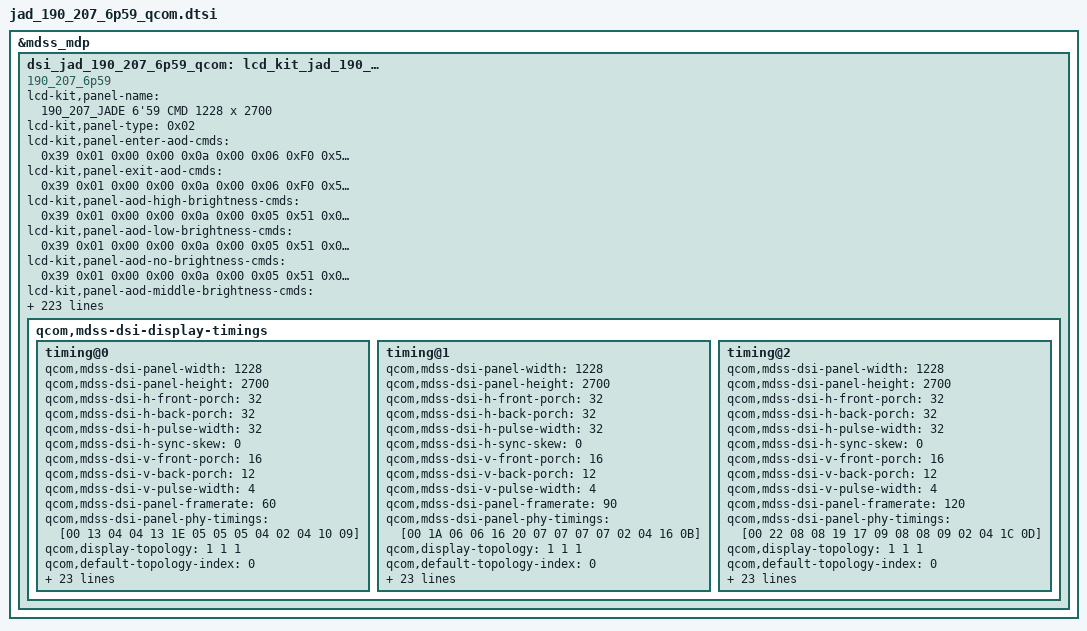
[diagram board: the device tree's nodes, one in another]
/* Copyright (c) 2013, The Linux Foundation. All rights reserved.
 *
 * This program is free software; you can redistribute it and/or modify
 * it under the terms of the GNU General Public License version 2 and
 * only version 2 as published by the Free Software Foundation.
 *
 * This program is distributed in the hope that it will be useful,
 * but WITHOUT ANY WARRANTY; without even the implied warranty of
 * MERCHANTABILITY or FITNESS FOR A PARTICULAR PURPOSE.  See the
 * GNU General Public License for more details.
 */

/*-------------------------------------------------------------------------
 * This file is autogenerated file using gcdb parser. Please do not edit it.
 * Update input XML file to add a new entry or update variable in this file
 * VERSION = 1.1
 *-----------------------------------------------------------------------*/
&mdss_mdp {
	dsi_jad_190_207_6p59_qcom: lcd_kit_jad_190_207_6p59_qcom {
		compatible = "190_207_6p59";
		lcd-kit,panel-name = "190_207_JADE 6'59 CMD 1228 x 2700";
		lcd-kit,panel-type = <0x02>;
		lcd-kit,panel-enter-aod-cmds = <0x39 0x01 0x00 0x00 0x0a 0x00 0x06 0xF0 0x55 0xAA 0x52 0x08 0x00
			0x15 0x01 0x00 0x00 0x0a 0x00 0x02 0x6F 0x0D
			0x15 0x01 0x00 0x00 0x0a 0x00 0x02 0xB5 0x50
			0x15 0x01 0x00 0x00 0x0a 0x00 0x02 0x2F 0x01
			0x05 0x01 0x00 0x00 0x0a 0x00 0x01 0x39
			0x05 0x01 0x00 0x00 0x0a 0x00 0x01 0x2C>;
		lcd-kit,panel-exit-aod-cmds = <0x39 0x01 0x00 0x00 0x0a 0x00 0x06 0xF0 0x55 0xAA 0x52 0x08 0x00
			0x15 0x01 0x00 0x00 0x0a 0x00 0x02 0x6F 0x0D
			0x15 0x01 0x00 0x00 0x0a 0x00 0x02 0xB5 0x4F
			0x05 0x01 0x00 0x00 0x0a 0x00 0x01 0x38
			0x05 0x01 0x00 0x00 0x0a 0x00 0x01 0x2C>;
		lcd-kit,panel-aod-high-brightness-cmds = <0x39 0x01 0x00 0x00 0x0a 0x00 0x05 0x51 0x00 0x00 0x0E 0xFE>;
		lcd-kit,panel-aod-low-brightness-cmds = <0x39 0x01 0x00 0x00 0x0a 0x00 0x05 0x51 0x00 0x00 0x07 0x5F>;
		lcd-kit,panel-aod-no-brightness-cmds = <0x39 0x01 0x00 0x00 0x0a 0x00 0x05 0x51 0x00 0x00 0x00 0x00>;
		lcd-kit,panel-aod-middle-brightness-cmds = <0x39 0x01 0x00 0x00 0x0a 0x00 0x05 0x51 0x00 0x00 0x0B 0xFE>;
		lcd-kit,panel-aod-off-cmds-state = "dsi_lp_mode";
		lcd-kit,pcd-check-reg-cmds = <0xcb>;
		lcd-kit,check-reg-on-cmds = <0x06 0x01 0x00 0x00 0x0a 0x00 0x01 0x0a>;
		lcd-kit,check-reg-on-value = <0x9c>;
		lcd-kit,check-aod-reg-on-cmds = <0x06 0x01 0x00 0x00 0x0a 0x00 0x01 0x0a>;
		lcd-kit,check-aod-reg-on-value = <0xdc>;
		lcd-kit,check-reg-off-cmds = <0x06 0x01 0x00 0x00 0x0a 0x00 0x01 0x0a>;
		lcd-kit,check-reg-off-value = <0x08>;
		lcd-kit,check-reg-on-cmds-state = "dsi_lp_mode";
		lcd-kit,check-aod-reg-on-cmds-state = "dsi_lp_mode";
		lcd-kit,check-reg-off-cmds-state = "dsi_lp_mode";
		lcd-kit,pcd-check-reg-value = <0xcb>;
		lcd-kit,pcd-errflag-check-support = <0>;
		lcd-kit,checksum-enable-cmds = <0x29 0x01 0x00 0x00 0x14 0x01 0x05 0xFF 0xAA 0x55 0xA5 0x80
			0x15 0x01 0x00 0x00 0x0a 0x00 0x02 0xF2 0x03>;
		lcd-kit,checksum-enable-cmds-state = "dsi_lp_mode";
		lcd-kit,checksum-disable-cmds = <0x29 0x01 0x00 0x00 0x14 0x01 0x05 0xFF 0xAA 0x55 0xA5 0x80
			0x15 0x01 0x00 0x00 0x0a 0x00 0x02 0xF2 0x00>;
		lcd-kit,checksum-disable-cmds-state = "dsi_lp_mode";
		lcd-kit,checksum-cmds = <0x15 0x01 0x00 0x00 0x0a 0x00 0x02 0x6F 0x01
			0x06 0x01 0x00 0x00 0x0a 0x00 0x08 0xF2 0x00 0x00 0x00 0x00 0x00 0x00 0x00>;
		lcd-kit,checksum-cmds-state = "dsi_lp_mode";
		lcd-kit,checksum-value = <0x92 0x54 0xc4 0x40 0x0e 0xf1 0x84 0x3b
			0x51 0x64 0xf8 0xae 0x2e 0x8a 0x47 0x0e
			0xcf 0x63 0xba 0xaa 0xfe 0x26 0xb6 0x54>;
		lcd-kit,oneside-mode-left = <0x39 0x01 0x00 0x00 0x00 0x00 0x06 0xF0 0x55 0xAA 0x52 0x08 0x06
		0x39 0x01 0x00 0x00 0x00 0x00 0x06 0xB0 0x32 0x32 0x32 0x32 0x32
		0x39 0x01 0x00 0x00 0x00 0x00 0x06 0xB1 0x32 0x32 0x32 0x32 0x32
		0x39 0x01 0x00 0x00 0x00 0x00 0x06 0xB2 0x32 0x32 0x32 0x32 0x32
		0x15 0x01 0x00 0x00 0x00 0x00 0x02 0xB3 0x32>;
		lcd-kit,oneside-mode-right = <0x39 0x01 0x00 0x00 0x00 0x00 0x06 0xF0 0x55 0xAA 0x52 0x08 0x06
		0x39 0x01 0x00 0x00 0x00 0x00 0x06 0xB6 0x32 0x32 0x32 0x32 0x32
		0x39 0x01 0x00 0x00 0x00 0x00 0x06 0xB7 0x32 0x32 0x32 0x32 0x32
		0x39 0x01 0x00 0x00 0x00 0x00 0x06 0xB8 0x32 0x32 0x32 0x32 0x32
		0x15 0x01 0x00 0x00 0x00 0x00 0x02 0xB9 0x32>;
		lcd-kit,oneside-mode-exit = <0x39 0x01 0x00 0x00 0x00 0x00 0x06 0xF0 0x55 0xAA 0x52 0x08 0x06
		0x39 0x01 0x00 0x00 0x00 0x00 0x06 0xB0 0x28 0x04 0x04 0x13 0x13
		0x39 0x01 0x00 0x00 0x00 0x00 0x06 0xB1 0x12 0x12 0x32 0x00 0x00
		0x39 0x01 0x00 0x00 0x00 0x00 0x06 0xB2 0x0F 0x0F 0x0E 0x0E 0x32
		0x15 0x01 0x00 0x00 0x00 0x00 0x02 0xB3 0x32
		0x39 0x01 0x00 0x00 0x00 0x00 0x06 0xB6 0x28 0x04 0x04 0x13 0x13
		0x39 0x01 0x00 0x00 0x00 0x00 0x06 0xB7 0x12 0x12 0x32 0x00 0x00
		0x39 0x01 0x00 0x00 0x00 0x00 0x06 0xB8 0x0F 0x0F 0x0E 0x0E 0x32
		0x15 0x01 0x00 0x00 0x00 0x00 0x02 0xB9 0x32>;
		lcd-kit,color-aod-detect-enter = <0x39 0x01 0x00 0x00 0x00 0x00 0x06 0xF0 0x55 0xAA 0x52 0x08 0x00
		0x15 0x01 0x00 0x00 0x00 0x00 0x02 0x6F 0x0D
		0x15 0x01 0x00 0x00 0x00 0x00 0x02 0xB5 0x50
		0x15 0x01 0x00 0x00 0x00 0x00 0x02 0x2F 0x01
		0x05 0x01 0x00 0x00 0x00 0x00 0x01 0x39
		0x05 0x01 0x00 0x00 0x00 0x00 0x01 0x2C
		0x39 0x01 0x00 0x00 0x00 0x00 0x05 0x51 0x00 0x00 0x0E 0xFE>;
		lcd-kit,color-aod-detect-enter-state = "dsi_lp_mode";
		lcd-kit,color-aod-detect-exit = <0x39 0x01 0x00 0x00 0x00 0x00 0x06 0xF0 0x55 0xAA 0x52 0x08 0x00
		0x15 0x01 0x00 0x00 0x00 0x00 0x02 0x6F 0x0D
		0x15 0x01 0x00 0x00 0x00 0x00 0x02 0xB5 0x4F
		0x05 0x01 0x00 0x00 0x00 0x00 0x01 0x38
		0x05 0x01 0x00 0x00 0x00 0x00 0x01 0x2C>;
		lcd-kit,color-aod-detect-exit-state = "dsi_lp_mode";
		lcd-kit,hor-line-cmds = <0x39 0x01 0x00 0x00 0x0a 0x00 0x06 0xF0 0x55 0xAA 0x52 0x08 0x00
			0x15 0x01 0x00 0x00 0x0a 0x00 0x02 0xB5 0x90
			0x15 0x01 0x00 0x00 0x0a 0x00 0x02 0x6F 0x06
			0x15 0x01 0x00 0x00 0x0a 0x00 0x02 0xB5 0x4E
			0x39 0x01 0x00 0x00 0x0a 0x00 0x06 0xF0 0x55 0xAA 0x52 0x08 0x01
			0x15 0x01 0x00 0x00 0x0a 0x00 0x02 0xB0 0x03
			0x15 0x01 0x00 0x00 0x0a 0x00 0x02 0xB3 0x15
			0x39 0x01 0x00 0x00 0x0a 0x00 0x06 0xF0 0x55 0xAA 0x52 0x08 0x01
			0x15 0x01 0x00 0x00 0x0a 0x00 0x02 0xB7 0x32
			0x39 0x01 0x00 0x00 0x0a 0x00 0x06 0xF0 0x55 0xAA 0x52 0x08 0x01
			0x15 0x01 0x00 0x00 0x0a 0x00 0x02 0xB1 0x05
			0x15 0x01 0x00 0x00 0x0a 0x00 0x02 0xB4 0x15
			0x39 0x01 0x00 0x00 0x0a 0x00 0x06 0xF0 0x55 0xAA 0x52 0x08 0x01
			0x15 0x01 0x00 0x00 0x0a 0x00 0x02 0xB8 0x5F
			0x29 0x01 0x00 0x00 0x0a 0x00 0x06 0xF0 0x55 0xAA 0x52 0x08 0x01
			0x29 0x01 0x00 0x00 0x0a 0x00 0x03 0xB5 0x00 0xF8
			0x29 0x01 0x00 0x00 0x0a 0x00 0x03 0xB6 0x01 0x68
			0x29 0x01 0x00 0x00 0x0a 0x00 0x06 0xF0 0x55 0xAA 0x52 0x08 0x01
			0x29 0x01 0x00 0x00 0x0a 0x00 0x02 0xCF 0x00
			0x29 0x01 0x00 0x00 0x0a 0x00 0x06 0xF0 0x55 0xAA 0x52 0x08 0x07
			0x29 0x01 0x00 0x00 0x0a 0x00 0x02 0xB0 0x00
			0x39 0x01 0x00 0x00 0x0a 0x00 0x06 0xF0 0x55 0xAA 0x52 0x08 0x06
			0x39 0x01 0x00 0x00 0x0a 0x00 0x06 0xB0 0x28 0x31 0x31 0x13 0x13
			0x39 0x01 0x00 0x00 0x0a 0x00 0x06 0xB1 0x12 0x12 0x32 0x31 0x31
			0x39 0x01 0x00 0x00 0x0a 0x00 0x06 0xB6 0x28 0x31 0x31 0x13 0x13
			0x39 0x01 0x00 0x00 0x0a 0x00 0x06 0xB7 0x12 0x12 0x32 0x31 0x31
			0x39 0x01 0x00 0x00 0x0a 0x00 0x06 0xF0 0x55 0xAA 0x52 0x08 0x03
			0x15 0x01 0x00 0x00 0x0a 0x00 0x02 0x6F 0x0F
			0x15 0x01 0x00 0x00 0x0a 0x00 0x02 0xB6 0x1F
			0x15 0x01 0x00 0x00 0x0a 0x00 0x02 0x6F 0x18
			0x15 0x01 0x00 0x00 0x0a 0x00 0x02 0xB6 0x0F
			0x15 0x01 0x00 0x00 0x0a 0x00 0x02 0x6F 0x21
			0x15 0x01 0x00 0x00 0x0a 0x00 0x02 0xB6 0x0F
			0x15 0x01 0x00 0x00 0x0a 0x00 0x02 0x6F 0x2A
			0x15 0x01 0x00 0x00 0x0a 0x00 0x02 0xB6 0x0F
			0x05 0x01 0x00 0x00 0x0a 0x00 0x01 0x35
			0x15 0x01 0x00 0x00 0x0a 0x00 0x02 0x53 0x20
			0x39 0x01 0x00 0x00 0x0a 0x00 0x05 0x51 0x00 0x00 0x00 0x00
			0x39 0x01 0x00 0x00 0x0a 0x00 0x05 0x2A 0x00 0x00 0x04 0xCB
			0x39 0x01 0x00 0x00 0x0a 0x00 0x05 0x2B 0x00 0x00 0x0A 0x8B
			0x15 0x01 0x00 0x00 0x0a 0x00 0x02 0x90 0x01
			0x15 0x01 0x00 0x00 0x0a 0x00 0x02 0x03 0x01
			0x39 0x01 0x00 0x00 0x64 0x00 0x13 0x91 0x89 0x28 0x00 0x3C 0xF2 0x00 0x04 0x01 0x06 0xF5 0x00 0x11 0x02 0x09 0x00 0xBF 0x10 0xF0
			0x05 0x01 0x00 0x00 0x0a 0x00 0x01 0x2C
			0x15 0x01 0x00 0x00 0x0a 0x00 0x02 0x82 0xAC
			0x05 0x01 0x00 0x00 0x46 0x01 0x01 0x11
			0x15 0x01 0x00 0x00 0x0a 0x00 0x02 0x2F 0x01
			0x05 0x01 0x00 0x00 0x0a 0x00 0x01 0x29>;
		lcd-kit,hor-line-cmds-state = "dsi_lp_mode";
		lcd-kit,start-pcd-check-cmds = <0x39 0x01 0x00 0x00 0x00 0x00 0x06 0xF0 0x55 0xAA 0x52 0x08 0x01
		0x39 0x01 0x00 0x00 0x00 0x00 0x03 0xD0 0x00 0x31>;
		lcd-kit,pcd-read-cmds = <0x39 0x01 0x00 0x00 0x00 0x00 0x06 0xF0 0x55 0xAA 0x52 0x08 0x01
		0x15 0x01 0x00 0x00 0x00 0x00 0x02 0x6F 0x02
		0x06 0x01 0x00 0x00 0x00 0x00 0x01 0xD0>;
		lcd-kit,pcd-read-cmds-state  = "dsi_lp_mode";
		lcd-kit,vtc-line-cmds = <0x39 0x01 0x00 0x00 0x0a 0x00 0x06 0xF0 0x55 0xAA 0x52 0x08 0x00
			0x15 0x01 0x00 0x00 0x0a 0x00 0x02 0xB5 0x90
			0x15 0x01 0x00 0x00 0x0a 0x00 0x02 0x6F 0x06
			0x15 0x01 0x00 0x00 0x0a 0x00 0x02 0xB5 0x4E
			0x39 0x01 0x00 0x00 0x0a 0x00 0x06 0xF0 0x55 0xAA 0x52 0x08 0x01
			0x15 0x01 0x00 0x00 0x0a 0x00 0x02 0xB0 0x03
			0x15 0x01 0x00 0x00 0x0a 0x00 0x02 0xB3 0x15
			0x39 0x01 0x00 0x00 0x0a 0x00 0x06 0xF0 0x55 0xAA 0x52 0x08 0x01
			0x15 0x01 0x00 0x00 0x0a 0x00 0x02 0xB7 0x32
			0x39 0x01 0x00 0x00 0x0a 0x00 0x06 0xF0 0x55 0xAA 0x52 0x08 0x01
			0x15 0x01 0x00 0x00 0x0a 0x00 0x02 0xB1 0x05
			0x15 0x01 0x00 0x00 0x0a 0x00 0x02 0xB4 0x15
			0x39 0x01 0x00 0x00 0x0a 0x00 0x06 0xF0 0x55 0xAA 0x52 0x08 0x01
			0x15 0x01 0x00 0x00 0x0a 0x00 0x02 0xB8 0x5F
			0x29 0x01 0x00 0x00 0x0a 0x00 0x06 0xF0 0x55 0xAA 0x52 0x08 0x01
			0x29 0x01 0x00 0x00 0x0a 0x00 0x03 0xB5 0x00 0xF8
			0x29 0x01 0x00 0x00 0x0a 0x00 0x03 0xB6 0x01 0x68
			0x29 0x01 0x00 0x00 0x0a 0x00 0x06 0xF0 0x55 0xAA 0x52 0x08 0x01
			0x29 0x01 0x00 0x00 0x0a 0x00 0x02 0xCF 0x00
			0x29 0x01 0x00 0x00 0x0a 0x00 0x06 0xF0 0x55 0xAA 0x52 0x08 0x07
			0x29 0x01 0x00 0x00 0x0a 0x00 0x02 0xB0 0x00
			0x39 0x01 0x00 0x00 0x0a 0x00 0x06 0xF0 0x55 0xAA 0x52 0x08 0x06
			0x39 0x01 0x00 0x00 0x0a 0x00 0x06 0xB0 0x28 0x31 0x31 0x13 0x13
			0x39 0x01 0x00 0x00 0x0a 0x00 0x06 0xB1 0x12 0x12 0x32 0x31 0x31
			0x39 0x01 0x00 0x00 0x0a 0x00 0x06 0xB6 0x28 0x31 0x31 0x13 0x13
			0x39 0x01 0x00 0x00 0x0a 0x00 0x06 0xB7 0x12 0x12 0x32 0x31 0x31
			0x39 0x01 0x00 0x00 0x0a 0x00 0x06 0xF0 0x55 0xAA 0x52 0x08 0x03
			0x15 0x01 0x00 0x00 0x0a 0x00 0x02 0x6F 0x0F
			0x15 0x01 0x00 0x00 0x0a 0x00 0x02 0xB6 0x1F
			0x15 0x01 0x00 0x00 0x0a 0x00 0x02 0x6F 0x18
			0x15 0x01 0x00 0x00 0x0a 0x00 0x02 0xB6 0x0F
			0x15 0x01 0x00 0x00 0x0a 0x00 0x02 0x6F 0x21
			0x15 0x01 0x00 0x00 0x0a 0x00 0x02 0xB6 0x0F
			0x15 0x01 0x00 0x00 0x0a 0x00 0x02 0x6F 0x2A
			0x15 0x01 0x00 0x00 0x0a 0x00 0x02 0xB6 0x0F
			0x05 0x01 0x00 0x00 0x0a 0x00 0x01 0x35
			0x15 0x01 0x00 0x00 0x0a 0x00 0x02 0x53 0x20
			0x39 0x01 0x00 0x00 0x0a 0x00 0x05 0x51 0x00 0x00 0x00 0x00
			0x39 0x01 0x00 0x00 0x0a 0x00 0x05 0x2A 0x00 0x00 0x04 0xCB
			0x39 0x01 0x00 0x00 0x0a 0x00 0x05 0x2B 0x00 0x00 0x0A 0x8B
			0x15 0x01 0x00 0x00 0x0a 0x00 0x02 0x90 0x01
			0x15 0x01 0x00 0x00 0x0a 0x00 0x02 0x03 0x01
			0x39 0x01 0x00 0x00 0x64 0x00 0x13 0x91 0x89 0x28 0x00 0x3C 0xF2 0x00 0x04 0x01 0x06 0xF5 0x00 0x11 0x02 0x09 0x00 0xBF 0x10 0xF0
			0x05 0x01 0x00 0x00 0x0a 0x00 0x01 0x2C
			0x15 0x01 0x00 0x00 0x0a 0x00 0x02 0x82 0xAC
			0x05 0x01 0x00 0x00 0x46 0x01 0x01 0x11
			0x15 0x01 0x00 0x00 0x0a 0x00 0x02 0x2F 0x01
			0x05 0x01 0x00 0x00 0x0a 0x00 0x01 0x29>;
		lcd-kit,vtc-line-cmds-state  = "dsi_lp_mode";
		lcd-kit,ddic-lv-det-enter1-cmds = <0x39 0x01 0x00 0x00 0x0a 0x00 0x06 0xF0 0x55 0xAA 0x52 0x08 0x01
			0x15 0x01 0x00 0x00 0x0a 0x00 0x02 0xC7 0xA0
			0x15 0x01 0x00 0x00 0x0a 0x00 0x02 0x6F 0x03
			0x15 0x01 0x00 0x00 0x0a 0x00 0x02 0xC7 0x18>;
		lcd-kit,ddic-lv-det-enter1-cmds-state  = "dsi_lp_mode";
		lcd-kit,ddic-lv-det-enter2-cmds = <0x39 0x01 0x00 0x00 0x0a 0x00 0x06 0xF0 0x55 0xAA 0x52 0x08 0x01
			0x15 0x01 0x00 0x00 0x0a 0x00 0x02 0xC7 0xA0
			0x15 0x01 0x00 0x00 0x0a 0x00 0x02 0x6F 0x03
			0x15 0x01 0x00 0x00 0x0a 0x00 0x02 0xC7 0x18>;
		lcd-kit,ddic-lv-det-enter2-cmds-state  = "dsi_lp_mode";
		lcd-kit,ddic-lv-det-enter3-cmds = <0x39 0x01 0x00 0x00 0x0a 0x00 0x06 0xF0 0x55 0xAA 0x52 0x08 0x01
			0x15 0x01 0x00 0x00 0x0a 0x00 0x02 0xC7 0xA0
			0x15 0x01 0x00 0x00 0x0a 0x00 0x02 0x6F 0x03
			0x15 0x01 0x00 0x00 0x0a 0x00 0x02 0xC7 0x18>;
		lcd-kit,ddic-lv-det-enter3-cmds-state  = "dsi_lp_mode";
		lcd-kit,ddic-lv-det-enter4-cmds = <0x39 0x01 0x00 0x00 0x0a 0x00 0x06 0xF0 0x55 0xAA 0x52 0x08 0x01
			0x15 0x01 0x00 0x00 0x0a 0x00 0x02 0xC7 0xA0
			0x15 0x01 0x00 0x00 0x0a 0x00 0x02 0x6F 0x03
			0x15 0x01 0x00 0x00 0x0a 0x00 0x02 0xC7 0x18>;
		lcd-kit,ddic-lv-det-enter4-cmds-state  = "dsi_lp_mode";
		lcd-kit,ddic-lv-det-rd1-cmds = <0x06 0x01 0x00 0x00 0x0a 0x00 0x01 0x0a>;
		lcd-kit,ddic-lv-det-rd1-cmds-state  = "dsi_lp_mode";
		lcd-kit,ddic-lv-det-rd2-cmds = <0x06 0x01 0x00 0x00 0x0a 0x00 0x01 0x0a>;
		lcd-kit,ddic-lv-det-rd2-cmds-state  = "dsi_lp_mode";
		lcd-kit,ddic-lv-det-rd3-cmds = <0x06 0x01 0x00 0x00 0x0a 0x00 0x01 0x0a>;
		lcd-kit,ddic-lv-det-rd3-cmds-state  = "dsi_lp_mode";
		lcd-kit,ddic-lv-det-rd4-cmds = <0x06 0x01 0x00 0x00 0x0a 0x00 0x01 0x0a>;
		lcd-kit,ddic-lv-det-rd4-cmds-state  = "dsi_lp_mode";
		lcd-kit,ddic-lv-det-value1 = <0x9c>;
		lcd-kit,ddic-lv-det-value2 = <0x9c>;
		lcd-kit,ddic-lv-det-value3 = <0x9c>;
		lcd-kit,ddic-lv-det-value4 = <0x9c>;
		lcd-kit,ap-aod-support = <1>;
		lcd-kit,left-time-to-te-us = <25667>;
		lcd-kit,right-time-to-te-us = <26167>;
		lcd-kit,te-interval-time-us = <16667>;
		lcd-kit,oneside-mode-support = <1>;
		lcd-kit,color-aod-detect-support = <1>;
		lcd-kit,elvdd-detect-support = <0>;
		lcd-kit,elvdd-detect-type = <2>;
		lcd-kit,elvdd-detect-value = <1>;
		lcd-kit,elvdd-delay = <50>;
		lcd-kit,elvdd-detect-gpio = <104>;
		lcd-kit,check-reg-on-support = <0>;
		lcd-kit,check-reg-on-support-dsm-report = <0>;
		lcd-kit,check-aod-reg-on-support = <0>;
		lcd-kit,check-aod-reg-on-support-dsm-report = <0>;
		lcd-kit,check-reg-off-support = <0>;
		lcd-kit,check-reg-off-support-dsm-report = <0>;
		lcd-kit,checksum-support = <1>;
		lcd-kit,pcd-cmds-support = <1>;
		lcd-kit,pcd-check-reg-value-compare-mode = <1>;
		lcd-kit,vtc-line-support = <1>;
		lcd-kit,ddic-lv-det-support = <1>;
		lcd-kit,hor-line-support = <1>;
		lcd-kit,hor-line-duration = <600>;
		qcom,mdss-dsi-panel-type = "dsi_cmd_mode";
		qcom,mdss-pan-physical-width-dimension = <69>;
		qcom,mdss-pan-physical-height-dimension = <152>;
		qcom,dsi-ctrl-num = <0>;
		qcom,dsi-phy-num = <0>;
		qcom,panel-supply-entries = <&dsi_panel_pwr_supply>;
		qcom,mdss-dsi-virtual-channel-id = <0>;
		qcom,mdss-dsi-h-sync-pulse = <0>;
		qcom,mdss-dsi-bllp-eof-power-mode;
		qcom,mdss-dsi-bllp-power-mode;
		qcom,mdss-dsi-dma-schedule-line = <1>;
		qcom,mdss-dsi-bpp = <24>;
		qcom,mdss-dsi-color-order = "rgb_swap_rgb";
		qcom,mdss-dsi-underflow-color = <0xff>;
		qcom,mdss-dsi-border-color = <0>;
		qcom,mdss-dsi-traffic-mode = "burst_mode";
		qcom,mdss-dsi-lane-map = "lane_map_0123";
		qcom,mdss-dsi-lane-0-state;
		qcom,mdss-dsi-lane-1-state;
		qcom,mdss-dsi-lane-2-state;
		qcom,mdss-dsi-lane-3-state;
		qcom,mdss-dsi-mdp-trigger = "none";
		qcom,mdss-dsi-dma-trigger = "trigger_sw";
		qcom,mdss-dsi-te-pin-select = <1>;
		qcom,mdss-dsi-wr-mem-start = <0x2c>;
		qcom,mdss-dsi-wr-mem-continue = <0x3c>;
		qcom,mdss-dsi-te-dcs-command = <1>;
		qcom,mdss-dsi-te-check-enable;
		qcom,mdss-dsi-te-using-te-pin;
		qcom,mdss-dsi-t-clk-post = <0>;
		qcom,mdss-dsi-t-clk-pre = <0>;
		qcom,dsi-select-clocks = "mux_byte_clk0", "mux_pixel_clk0";
		qcom,mdss-dsi-stream = <0>;
		qcom,mdss-dsi-lp11-init;
		qcom,sublinks-count = <2>;
		qcom,lanes-per-sublink = <2>;
		qcom,mdss-dsi-panel-hdr-color-primaries = <14500 15500 32000 17000 15500 30000 8000 3000>;
		qcom,mdss-dsi-panel-peak-brightness = <4200000>;
		qcom,mdss-dsi-panel-blackness-level = <3230>;
		qcom,dynamic-mode-switch-enabled;
		qcom,dynamic-mode-switch-type = "dynamic-resolution-switch-immediate";
		qcom,mdss-dsi-bl-pmic-control-type = "bl_ctrl_dcs";
		qcom,mdss-dsi-bl-min-level = <1>;
		qcom,mdss-dsi-bl-max-level = <4095>;
		qcom,esd-check-enabled;
		qcom,mdss-dsi-panel-status-command = [06 01 00 00 00 00 01 0A];
		qcom,mdss-dsi-panel-status-command-state = "dsi_lp_mode";
		qcom,mdss-dsi-panel-status-check-mode = "reg_read";
		qcom,mdss-dsi-panel-status-read-length = <1>;
		qcom,mdss-dsi-panel-status-value = <0x9C>;
		lcd-kit,power-on-stage = <2 1 1
				9 1 1
				3 1 1
				1 1 10
				5 1 10
				7 1 0
				6 1 0
				8 1 0>;
		lcd-kit,lp-on-stage = <0 0 0>;
		lcd-kit,lp-off-stage = <0 0 0>;
		lcd-kit,power-off-stage = <7 0 0
				6 0 0
				8 0 0
				5 0 1
				1 0 1
				9 0 1
				3 0 1
				2 0 1>;
		lcd-kit,only-power-off-stage = <0 0 0>;
		lcd-kit,pt-support = <1>;
		lcd-kit,panel-on-always-reset = <0>;
		lcd-kit,lcd-vci = <1 13 3000000 3000000 3000000 10000 80>;
		lcd-kit,lcd-iovcc = <1 12 1800000 1800000 1800000 60700 80>;
		lcd-kit,lcd-vdd = <2 197 1200000>;
		lcd-kit,lcd-vsp = <1 1 1200000 1200000 1200000 60700 80>;
		lcd-kit,lcd-reset = <2 24 0>;
		lcd-kit,lcd-vci-name = "vdd";
		lcd-kit,lcd-iovcc-name = "vddio";
		lcd-kit,lcd-vsp-name = "ddic";
		lcd-kit,project-id-support = <0>;
		lcd-kit,default-project-id = "G240A7130";
		lcd-kit,sn-code-support = <1>;
		lcd-kit,oem-info-support = <1>;
		lcd-kit,oem-barcode-2d-support = <1>;
		lcd-kit,oem-barcode-2d-num-offset = <0>;
		lcd-kit,barcode-2d-cmds = <0x39 0x01 0x00 0x00 0x0a 0x00 0x06 0xF0 0x55 0xAA 0x52 0x08 0x01
                  0x14 0x01 0x00 0x00 0x0a 0x00 0x08 0xD6 0x00 0x00 0x00 0x00 0x00 0x00 0x00
                  0x14 0x01 0x00 0x00 0x0a 0x00 0x07 0xD7 0x00 0x00 0x00 0x00 0x00 0x00
                  0x14 0x01 0x00 0x00 0x0a 0x00 0x06 0xBF 0x00 0x00 0x00 0x00 0x00>;
		lcd-kit,barcode-2d-cmds-state = "dsi_lp_mode";
		lcd-kit,panel-getblmaxnit-type = <0>;
		lcd-kit,panel-blmaxnit-min-value = <400>;
		lcd-kit,inversion-support = <0>;
		lcd-kit,panel-gpio-offset = <308>;
		lcd-kit,finger-unlock-state-support = <1>;
		lcd-kit,panel-bl-max-nit = <450>;
		lcd-kit,panel-bl-min = <3>;
		lcd-kit,panel-bl-max = <10000>;
		lcd-kit,panel-bl-def = <2074>;
		lcd-kit,check-reg-support = <0>;
		lcd-kit,thp-proximity-support = <0>;
		lcd-kit,proximity-reset-delay-min = <65>;
		lcd-kit,backlight-cmds = <0x39 0x01 0x00 0x00 0x00 0x00 0x03 0x51 0x00 0x00>;
		lcd-kit,backlight-cmds-state = "dsi_lp_mode";
		lcd-kit,backlight-order = <0>;
		lcd-kit,backlight-need-sync = <0>;
		lcd-kit,fps-support = <1>;
		lcd-kit,default-fps = <60>;
		lcd-kit,panel-support-fps-list = <60 90 120>;
		qcom,mdss-dsi-display-timings {
			timing@0 {
				qcom,mdss-dsi-panel-width = <1228>;
				qcom,mdss-dsi-panel-height = <2700>;
				qcom,mdss-dsi-h-front-porch = <32>;
				qcom,mdss-dsi-h-back-porch = <32>;
				qcom,mdss-dsi-h-pulse-width = <32>;
				qcom,mdss-dsi-h-sync-skew = <0>;
				qcom,mdss-dsi-v-front-porch = <16>;
				qcom,mdss-dsi-v-back-porch = <12>;
				qcom,mdss-dsi-v-pulse-width = <4>;
				qcom,mdss-dsi-panel-framerate = <60>;
				qcom,mdss-dsi-panel-phy-timings= [00 13 04 04 13 1E 05
			05 05 04 02 04 10 09];
				qcom,display-topology  = <1 1 1>;
				qcom,default-topology-index  = <0>;
				qcom,mdss-dsi-on-command = [39 01 00 00 00 00 06 F0 55 AA 52 08 03
		15 01 00 00 00 00 02 6F 0F
		15 01 00 00 00 00 02 B6 1F
		15 01 00 00 00 00 02 6F 18
		15 01 00 00 00 00 02 B6 0F
		15 01 00 00 00 00 02 6F 21
		15 01 00 00 00 00 02 B6 0F
		15 01 00 00 00 00 02 6F 2A
		15 01 00 00 00 00 02 B6 0F
		05 01 00 00 00 00 01 35
		15 01 00 00 00 00 02 53 20
		39 01 00 00 00 00 05 51 00 00 00 00
		39 01 00 00 00 00 05 2A 00 00 04 CB
		39 01 00 00 00 00 05 2B 00 00 0A 8B
		15 01 00 00 00 00 02 90 01
		15 01 00 00 00 00 02 03 01
		39 01 00 00 01 00 13 91 89 28 00 3C F2 00 04 01 06 F5 00 11 02 09 00 BF 10 F0
		05 01 00 00 00 00 01 2C
		15 01 00 00 00 00 02 82 AC
		15 01 00 00 00 00 02 2F 01
		39 01 00 00 00 00 06 F0 55 AA 52 08 00
		15 01 00 00 00 00 02 B5 94
		15 01 00 00 00 00 02 6F 06
		39 01 00 00 00 00 04 B5 4E 23 50
		15 01 00 00 00 00 02 6F 0B
		39 01 00 00 00 00 04 B5 4E 2A 50
		15 01 00 00 00 00 02 6F 10
		39 01 00 00 00 00 06 B5 23 23 23 23 23
		39 01 00 00 00 00 05 BE 0E 09 14 13
		39 01 00 00 00 00 06 F0 55 AA 52 08 01
		39 01 00 00 00 00 04 D1 07 4A 40
		15 01 00 00 00 00 02 6F 02
		15 01 00 00 00 00 02 D2 11
		05 01 00 00 46 00 01 11
		05 01 00 00 00 00 01 29];
				qcom,mdss-dsi-on-command-state = "dsi_lp_mode";
				qcom,mdss-dsi-off-command = [05 01 00 00 14 00 01 28
			05 01 00 00 78 00 01 10];
				qcom,mdss-dsi-off-command-state = "dsi_lp_mode";
				qcom,compression-mode = "dsc";
				qcom,mdss-dsc-slice-height = <60>;
				qcom,mdss-dsc-slice-width = <1228>;
				qcom,mdss-dsc-slice-per-pkt = <1>;
				qcom,mdss-dsc-bit-per-component = <8>;
				qcom,mdss-dsc-bit-per-pixel = <8>;
				qcom,mdss-dsc-block-prediction-enable;
				qcom,mdss-dsi-timing-switch-command = [15 01 00 00 11 00 02 2F 01];
				qcom,mdss-dsi-timing-switch-command-state = "dsi_lp_mode";
				qcom,mdss-dsi-lp1-command = [39 01 00 00 00 00 06 F0 55 AA 52 08 00
			15 01 00 00 00 00 02 6F 0D
			15 01 00 00 00 00 02 B5 50
			15 01 00 00 00 00 02 2F 01
			05 01 00 00 00 00 01 39
			05 01 00 00 00 00 01 2C];
				qcom,mdss-dsi-lp1-command-state = "dsi_lp_mode";
				qcom,mdss-dsi-nolp-command = [39 01 00 00 00 00 06 F0 55 AA 52 08 00
			15 01 00 00 00 00 02 6F 0D
			15 01 00 00 00 00 02 B5 4F
			05 01 00 00 00 00 01 38
			05 01 00 00 00 00 01 2C
			15 01 00 00 00 00 02 2F 01];
				qcom,mdss-dsi-nolp-command-state = "dsi_lp_mode";
			};
			timing@1 {
				qcom,mdss-dsi-panel-width = <1228>;
				qcom,mdss-dsi-panel-height = <2700>;
				qcom,mdss-dsi-h-front-porch = <32>;
				qcom,mdss-dsi-h-back-porch = <32>;
				qcom,mdss-dsi-h-pulse-width = <32>;
				qcom,mdss-dsi-h-sync-skew = <0>;
				qcom,mdss-dsi-v-front-porch = <16>;
				qcom,mdss-dsi-v-back-porch = <12>;
				qcom,mdss-dsi-v-pulse-width = <4>;
				qcom,mdss-dsi-panel-framerate = <90>;
				qcom,mdss-dsi-panel-phy-timings= [00 1A 06 06 16 20 07
			07 07 07 02 04 16 0B];
				qcom,display-topology  = <1 1 1>;
				qcom,default-topology-index  = <0>;
				qcom,mdss-dsi-on-command = [39 01 00 00 00 00 06 F0 55 AA 52 08 03
		15 01 00 00 00 00 02 6F 0F
		15 01 00 00 00 00 02 B6 1F
		15 01 00 00 00 00 02 6F 18
		15 01 00 00 00 00 02 B6 0F
		15 01 00 00 00 00 02 6F 21
		15 01 00 00 00 00 02 B6 0F
		15 01 00 00 00 00 02 6F 2A
		15 01 00 00 00 00 02 B6 0F
		05 01 00 00 00 00 01 35
		15 01 00 00 00 00 02 53 20
		39 01 00 00 00 00 05 51 00 00 00 00
		39 01 00 00 00 00 05 2A 00 00 04 CB
		39 01 00 00 00 00 05 2B 00 00 0A 8B
		15 01 00 00 00 00 02 90 01
		15 01 00 00 00 00 02 03 01
		39 01 00 00 01 00 13 91 89 28 00 3C F2 00 04 01 06 F5 00 11 02 09 00 BF 10 F0
		05 01 00 00 00 00 01 2C
		15 01 00 00 00 00 02 82 AC
		15 01 00 00 00 00 02 2F 01
		39 01 00 00 00 00 06 F0 55 AA 52 08 00
		15 01 00 00 00 00 02 B5 94
		15 01 00 00 00 00 02 6F 06
		39 01 00 00 00 00 04 B5 4E 23 50
		15 01 00 00 00 00 02 6F 0B
		39 01 00 00 00 00 04 B5 4E 2A 50
		15 01 00 00 00 00 02 6F 10
		39 01 00 00 00 00 06 B5 23 23 23 23 23
		39 01 00 00 00 00 05 BE 0E 09 14 13
		39 01 00 00 00 00 06 F0 55 AA 52 08 01
		39 01 00 00 00 00 04 D1 07 4A 40
		15 01 00 00 00 00 02 6F 02
		15 01 00 00 00 00 02 D2 11
		05 01 00 00 46 00 01 11
		15 01 00 00 00 00 02 2F 02
		05 01 00 00 00 00 01 29];
				qcom,mdss-dsi-on-command-state = "dsi_lp_mode";
				qcom,mdss-dsi-off-command = [05 01 00 00 14 00 01 28
			05 01 00 00 78 00 01 10];
				qcom,mdss-dsi-off-command-state = "dsi_lp_mode";
				qcom,compression-mode = "dsc";
				qcom,mdss-dsc-slice-height = <60>;
				qcom,mdss-dsc-slice-width = <1228>;
				qcom,mdss-dsc-slice-per-pkt = <1>;
				qcom,mdss-dsc-bit-per-component = <8>;
				qcom,mdss-dsc-bit-per-pixel = <8>;
				qcom,mdss-dsc-block-prediction-enable;
				qcom,mdss-dsi-timing-switch-command = [15 01 00 00 11 00 02 2F 02];
				qcom,mdss-dsi-timing-switch-command-state = "dsi_lp_mode";
				qcom,mdss-dsi-lp1-command = [39 01 00 00 00 00 06 F0 55 AA 52 08 00
			15 01 00 00 00 00 02 6F 0D
			15 01 00 00 00 00 02 B5 50
			15 01 00 00 00 00 02 2F 01
			05 01 00 00 00 00 01 39
			05 01 00 00 00 00 01 2C];
				qcom,mdss-dsi-lp1-command-state = "dsi_lp_mode";
				qcom,mdss-dsi-nolp-command = [39 01 00 00 00 00 06 F0 55 AA 52 08 00
			15 01 00 00 00 00 02 6F 0D
			15 01 00 00 00 00 02 B5 4F
			05 01 00 00 00 00 01 38
			05 01 00 00 00 00 01 2C
			15 01 00 00 00 00 02 2F 02];
				qcom,mdss-dsi-nolp-command-state = "dsi_lp_mode";
			};
			timing@2 {
				qcom,mdss-dsi-panel-width = <1228>;
				qcom,mdss-dsi-panel-height = <2700>;
				qcom,mdss-dsi-h-front-porch = <32>;
				qcom,mdss-dsi-h-back-porch = <32>;
				qcom,mdss-dsi-h-pulse-width = <32>;
				qcom,mdss-dsi-h-sync-skew = <0>;
				qcom,mdss-dsi-v-front-porch = <16>;
				qcom,mdss-dsi-v-back-porch = <12>;
				qcom,mdss-dsi-v-pulse-width = <4>;
				qcom,mdss-dsi-panel-framerate = <120>;
				qcom,mdss-dsi-panel-phy-timings= [00 22 08 08 19 17 09
			08 08 09 02 04 1C 0D];
				qcom,display-topology  = <1 1 1>;
				qcom,default-topology-index  = <0>;
				qcom,mdss-dsi-on-command = [39 01 00 00 00 00 06 F0 55 AA 52 08 03
		15 01 00 00 00 00 02 6F 0F
		15 01 00 00 00 00 02 B6 1F
		15 01 00 00 00 00 02 6F 18
		15 01 00 00 00 00 02 B6 0F
		15 01 00 00 00 00 02 6F 21
		15 01 00 00 00 00 02 B6 0F
		15 01 00 00 00 00 02 6F 2A
		15 01 00 00 00 00 02 B6 0F
		05 01 00 00 00 00 01 35
		15 01 00 00 00 00 02 53 20
		39 01 00 00 00 00 05 51 00 00 00 00
		39 01 00 00 00 00 05 2A 00 00 04 CB
		39 01 00 00 00 00 05 2B 00 00 0A 8B
		15 01 00 00 00 00 02 90 01
		15 01 00 00 00 00 02 03 01
		39 01 00 00 01 00 13 91 89 28 00 3C F2 00 04 01 06 F5 00 11 02 09 00 BF 10 F0
		05 01 00 00 00 00 01 2C
		15 01 00 00 00 00 02 82 AC
		15 01 00 00 00 00 02 2F 01
		39 01 00 00 00 00 06 F0 55 AA 52 08 00
		15 01 00 00 00 00 02 B5 94
		15 01 00 00 00 00 02 6F 06
		39 01 00 00 00 00 04 B5 4E 23 50
		15 01 00 00 00 00 02 6F 0B
		39 01 00 00 00 00 04 B5 4E 2A 50
		15 01 00 00 00 00 02 6F 10
		39 01 00 00 00 00 06 B5 23 23 23 23 23
		39 01 00 00 00 00 05 BE 0E 09 14 13
		39 01 00 00 00 00 06 F0 55 AA 52 08 01
		39 01 00 00 00 00 04 D1 07 4A 40
		15 01 00 00 00 00 02 6F 02
		15 01 00 00 00 00 02 D2 11
		05 01 00 00 46 00 01 11
		15 01 00 00 00 00 02 2F 03
		05 01 00 00 00 00 01 29];
				qcom,mdss-dsi-on-command-state = "dsi_lp_mode";
				qcom,mdss-dsi-off-command = [05 01 00 00 14 00 01 28
			05 01 00 00 78 00 01 10];
				qcom,mdss-dsi-off-command-state = "dsi_lp_mode";
				qcom,compression-mode = "dsc";
				qcom,mdss-dsc-slice-height = <60>;
				qcom,mdss-dsc-slice-width = <1228>;
				qcom,mdss-dsc-slice-per-pkt = <1>;
				qcom,mdss-dsc-bit-per-component = <8>;
				qcom,mdss-dsc-bit-per-pixel = <8>;
				qcom,mdss-dsc-block-prediction-enable;
				qcom,mdss-dsi-timing-switch-command = [15 01 00 00 00 00 02 2F 03];
				qcom,mdss-dsi-timing-switch-command-state = "dsi_lp_mode";
				qcom,mdss-dsi-lp1-command = [39 01 00 00 00 00 06 F0 55 AA 52 08 00
			15 01 00 00 00 00 02 6F 0D
			15 01 00 00 00 00 02 B5 50
			15 01 00 00 00 00 02 2F 01
			05 01 00 00 00 00 01 39
			05 01 00 00 00 00 01 2C];
				qcom,mdss-dsi-lp1-command-state = "dsi_lp_mode";
				qcom,mdss-dsi-nolp-command = [39 01 00 00 00 00 06 F0 55 AA 52 08 00
			15 01 00 00 00 00 02 6F 0D
			15 01 00 00 00 00 02 B5 4F
			05 01 00 00 00 00 01 38
			05 01 00 00 00 00 01 2C
			15 01 00 00 00 00 02 2F 03];
				qcom,mdss-dsi-nolp-command-state = "dsi_lp_mode";
			};
		};
    };
};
